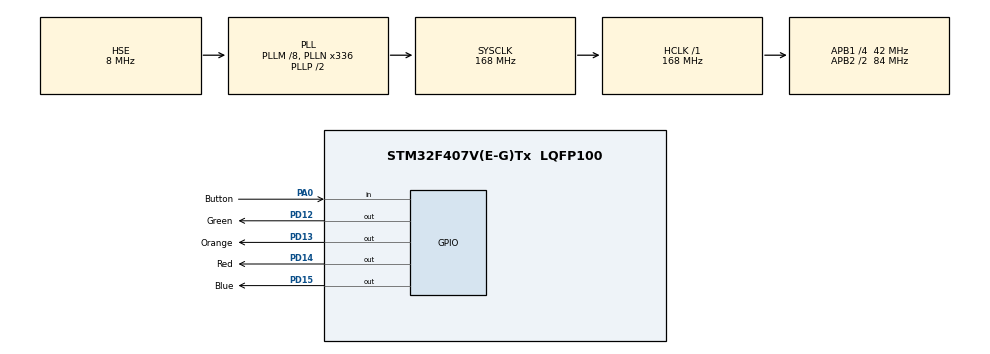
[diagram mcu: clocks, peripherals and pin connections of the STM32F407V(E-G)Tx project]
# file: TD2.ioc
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Mcu.Family=STM32F4
Mcu.Name=STM32F407V(E-G)Tx
Mcu.Package=LQFP100
NVIC.PriorityGroup=NVIC_PRIORITYGROUP_0
PA0-WKUP.GPIO_Label=Button
PA0-WKUP.Signal=GPIO_Input
PA13.Mode=Serial_Wire
PA13.Signal=SYS_JTMS-SWDIO
PA14.Mode=Serial_Wire
PA14.Signal=SYS_JTCK-SWCLK
PD12.GPIO_Label=Green
PD12.GPIO_Speed=GPIO_SPEED_FREQ_HIGH
PD12.Signal=GPIO_Output
PD13.GPIO_Label=Orange
PD13.GPIO_Speed=GPIO_SPEED_FREQ_HIGH
PD13.Signal=GPIO_Output
PD14.GPIO_Label=Red
PD14.GPIO_Speed=GPIO_SPEED_FREQ_HIGH
PD14.Signal=GPIO_Output
PD15.GPIO_Label=Blue
PD15.GPIO_Speed=GPIO_SPEED_FREQ_HIGH
PD15.Signal=GPIO_Output
PH0-OSC_IN.Mode=HSE-External-Oscillator
PH0-OSC_IN.Signal=RCC_OSC_IN
PH1-OSC_OUT.Mode=HSE-External-Oscillator
PH1-OSC_OUT.Signal=RCC_OSC_OUT
ProjectManager.HeapSize=0x200
ProjectManager.StackSize=0x400
ProjectManager.TargetToolchain=STM32CubeIDE
RCC.48MHZClocksFreq_Value=48000000
RCC.AHBFreq_Value=168000000
RCC.APB1CLKDivider=RCC_HCLK_DIV4
RCC.APB1Freq_Value=42000000
RCC.APB1TimFreq_Value=84000000
RCC.APB2CLKDivider=RCC_HCLK_DIV2
RCC.APB2Freq_Value=84000000
RCC.APB2TimFreq_Value=168000000
RCC.CortexFreq_Value=168000000
RCC.HCLKFreq_Value=168000000
RCC.HSE_VALUE=8000000
RCC.HSI_VALUE=16000000
RCC.LSE_VALUE=32768
RCC.PLLM=8
RCC.PLLN=336
RCC.PLLQ=7
RCC.PLLSourceVirtual=RCC_PLLSOURCE_HSE
RCC.SYSCLKFreq_VALUE=168000000
RCC.SYSCLKSource=RCC_SYSCLKSOURCE_PLLCLK
RCC.VCOOutputFreq_Value=336000000
board=STM32F407G-DISC1

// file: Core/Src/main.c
/* USER CODE BEGIN Header */
/**
  ******************************************************************************
  * @file           : main.c
  * @brief          : Main program body
  ******************************************************************************
  * @attention
  *
  * Copyright (c) 2023 STMicroelectronics.
  * All rights reserved.
  *
  * This software is licensed under terms that can be found in the LICENSE file
  * in the root directory of this software component.
  * If no LICENSE file comes with this software, it is provided AS-IS.
  *
  ******************************************************************************
  */
/* USER CODE END Header */
#include "main.h"

/* USER CODE BEGIN PV */
int toto = 0;
int button = 0;
int indicator = 0;
double dummyclock = 0;
/* USER CODE END PV */

void SystemClock_Config(void);
static void MX_GPIO_Init(void);
void tempo(double tempo);
uint16_t factorielle (int n);

int main(void)
{

  /* MCU Configuration--------------------------------------------------------*/

  /* Reset of all peripherals, Initializes the Flash interface and the Systick. */
  HAL_Init();

  /* Configure the system clock */
  SystemClock_Config();

  /* Initialize all configured peripherals */
  MX_GPIO_Init();

  /* Infinite loop */
  /* USER CODE BEGIN WHILE */
  while (1)
  {

	  /*
	   * 1.1
	   * if (HAL_GPIO_ReadPin(GPIOA,Button_Pin)){
		  HAL_GPIO_WritePin(GPIOD, Red_Pin,1);
	  	  }
	   * */

	  /* 1.2
	   * if (HAL_GPIO_ReadPin(GPIOA,Button_Pin)){
	   *	  HAL_GPIO_WritePin(GPIOD, Red_Pin,1);
	   *  }else{
	   *  	  HAL_GPIO_WritePin(GPIOD, Red_Pin,0);
	   *  }
	   *
	   */

	  /*
	   * 1.3
	   * button = HAL_GPIO_ReadPin(GPIOA,Button_Pin);
	  indicator = (button<<1) | toto;

	  switch (indicator){

		  case 0b00:
		  {
			 HAL_GPIO_WritePin(GPIOD, Green_Pin,0);
			 HAL_GPIO_WritePin(GPIOD, Orange_Pin,0);
			 HAL_GPIO_WritePin(GPIOD, Red_Pin,0);
			 HAL_GPIO_WritePin(GPIOD, Blue_Pin,1);
			 break;
		  }
		  case 0b01:
		  {
			  HAL_GPIO_WritePin(GPIOD, Green_Pin,0);
			  HAL_GPIO_WritePin(GPIOD, Orange_Pin,1);
			  HAL_GPIO_WritePin(GPIOD, Red_Pin,1);
			  HAL_GPIO_WritePin(GPIOD, Blue_Pin,0);
			  break;
		  }
		  case 0b10:
		  {
			  HAL_GPIO_WritePin(GPIOD, Green_Pin,1);
			  HAL_GPIO_WritePin(GPIOD, Orange_Pin,0);
			  HAL_GPIO_WritePin(GPIOD, Red_Pin,1);
			  HAL_GPIO_WritePin(GPIOD, Blue_Pin,0);
			  break;
		  }
		  case 0b11:
		  {
			  HAL_GPIO_WritePin(GPIOD, Green_Pin,0);
			  HAL_GPIO_WritePin(GPIOD, Orange_Pin,1);
			  HAL_GPIO_WritePin(GPIOD, Red_Pin,0);
			  HAL_GPIO_WritePin(GPIOD, Blue_Pin,0);
			  break;
		  }
	  }
	   * */

	  /*
	   *  2.1
	  	  dummyclock = 0;
	  	  HAL_GPIO_TogglePin(GPIOD, Green_Pin);
	  	  while (dummyclock < 999999999999999999){dummyclock++;}
	   * */

	  /*
	   * 2.2
	   	  dummyclock = 0;
	  	  HAL_GPIO_TogglePin(GPIOD, Green_Pin);
	  	  do{
		  	  dummyclock++;
	  	  }
  	  	  while(dummyclock < 999);
	   * */

	  /*
	   * 2.3
	   * max n value = 8
	  uint16_t n = 5;
	  uint16_t res = 1;
	  for (int i = 1; i<=n;i++){
		  res*=i;
	  }
	   * */
    /* USER CODE END WHILE */

  }
}

void SystemClock_Config(void)
{
  RCC_OscInitTypeDef RCC_OscInitStruct = {0};
  RCC_ClkInitTypeDef RCC_ClkInitStruct = {0};

  /** Configure the main internal regulator output voltage
  */
  __HAL_RCC_PWR_CLK_ENABLE();
  __HAL_PWR_VOLTAGESCALING_CONFIG(PWR_REGULATOR_VOLTAGE_SCALE1);

  /** Initializes the RCC Oscillators according to the specified parameters
  * in the RCC_OscInitTypeDef structure.
  */
  RCC_OscInitStruct.OscillatorType = RCC_OSCILLATORTYPE_HSE;
  RCC_OscInitStruct.HSEState = RCC_HSE_ON;
  RCC_OscInitStruct.PLL.PLLState = RCC_PLL_ON;
  RCC_OscInitStruct.PLL.PLLSource = RCC_PLLSOURCE_HSE;
  RCC_OscInitStruct.PLL.PLLM = 8;
  RCC_OscInitStruct.PLL.PLLN = 336;
  RCC_OscInitStruct.PLL.PLLP = RCC_PLLP_DIV2;
  RCC_OscInitStruct.PLL.PLLQ = 7;
  if (HAL_RCC_OscConfig(&RCC_OscInitStruct) != HAL_OK)
  {
    Error_Handler();
  }

  /** Initializes the CPU, AHB and APB buses clocks
  */
  RCC_ClkInitStruct.ClockType = RCC_CLOCKTYPE_HCLK|RCC_CLOCKTYPE_SYSCLK
                              |RCC_CLOCKTYPE_PCLK1|RCC_CLOCKTYPE_PCLK2;
  RCC_ClkInitStruct.SYSCLKSource = RCC_SYSCLKSOURCE_PLLCLK;
  RCC_ClkInitStruct.AHBCLKDivider = RCC_SYSCLK_DIV1;
  RCC_ClkInitStruct.APB1CLKDivider = RCC_HCLK_DIV4;
  RCC_ClkInitStruct.APB2CLKDivider = RCC_HCLK_DIV2;

  if (HAL_RCC_ClockConfig(&RCC_ClkInitStruct, FLASH_LATENCY_5) != HAL_OK)
  {
    Error_Handler();
  }
}

static void MX_GPIO_Init(void)
{
  GPIO_InitTypeDef GPIO_InitStruct = {0};

  /* GPIO Ports Clock Enable */
  __HAL_RCC_GPIOH_CLK_ENABLE();
  __HAL_RCC_GPIOA_CLK_ENABLE();
  __HAL_RCC_GPIOD_CLK_ENABLE();

  /*Configure GPIO pin Output Level */
  HAL_GPIO_WritePin(GPIOD, Green_Pin|Orange_Pin|Red_Pin|Blue_Pin, GPIO_PIN_RESET);

  /*Configure GPIO pin : Button_Pin */
  GPIO_InitStruct.Pin = Button_Pin;
  GPIO_InitStruct.Mode = GPIO_MODE_INPUT;
  GPIO_InitStruct.Pull = GPIO_NOPULL;
  HAL_GPIO_Init(Button_GPIO_Port, &GPIO_InitStruct);

  /*Configure GPIO pins : Green_Pin Orange_Pin Red_Pin Blue_Pin */
  GPIO_InitStruct.Pin = Green_Pin|Orange_Pin|Red_Pin|Blue_Pin;
  GPIO_InitStruct.Mode = GPIO_MODE_OUTPUT_PP;
  GPIO_InitStruct.Pull = GPIO_NOPULL;
  GPIO_InitStruct.Speed = GPIO_SPEED_FREQ_HIGH;
  HAL_GPIO_Init(GPIOD, &GPIO_InitStruct);

}

/* USER CODE BEGIN 4 */
void tempo(double tempo){
	double dummyclock = 0;
	while (dummyclock < tempo){dummyclock++;}
}

uint16_t factorielle(int n){
	uint16_t res = 1;
	for (int i = 1; i<=n;i++){
		res*=i;
	}
	return res;
}

/* USER CODE END 4 */

void Error_Handler(void)
{
  __disable_irq();
  while (1)
  {
  }
}
